AUTOSAR XML (schema 314)
package /ComponentType
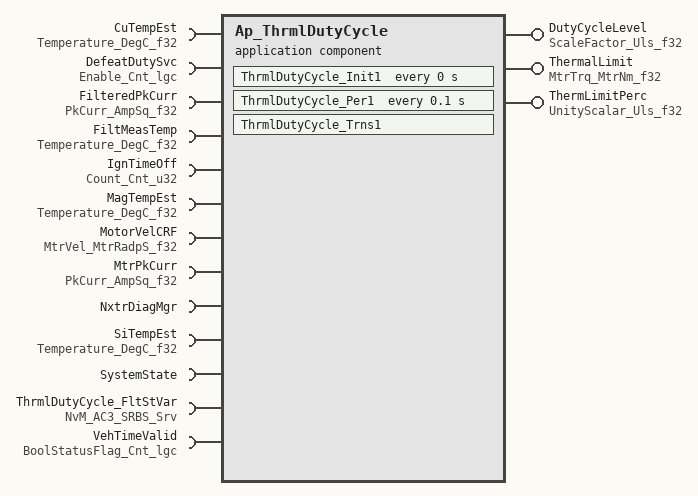
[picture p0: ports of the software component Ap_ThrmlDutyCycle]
  application software component type Ap_ThrmlDutyCycle
    provide port DutyCycleLevel: unqueued-sender-com-spec{data-element=Uls_f32, can-invalidate=false, init-value=D_ZERO_ULS_F32}, provided-interface=ScaleFactor_Uls_f32
    provide port ThermalLimit: unqueued-sender-com-spec{data-element=MtrNm_f32, can-invalidate=false, init-value=D_MTRTRQCMDHILMT_MTRNM_F32}, provided-interface=MtrTrq_MtrNm_f32
    provide port ThermLimitPerc: unqueued-sender-com-spec{data-element=Uls_f32, can-invalidate=false, init-value=D_ZERO_ULS_F32}, provided-interface=UnityScalar_Uls_f32
    13 x require port:
      CuTempEst: unqueued-receiver-com-spec{data-element=DegC_f32, init-value=D_ZERO_ULS_F32}, required-interface=Temperature_DegC_f32
      DefeatDutySvc: unqueued-receiver-com-spec{data-element=Cnt_lgc, init-value=D_FALSE_CNT_LGC}, required-interface=Enable_Cnt_lgc
      FilteredPkCurr: unqueued-receiver-com-spec{data-element=AmpSq_f32, init-value=D_ZERO_ULS_F32}, required-interface=PkCurr_AmpSq_f32
      FiltMeasTemp: unqueued-receiver-com-spec{data-element=DegC_f32, init-value=D_ZERO_ULS_F32}, required-interface=Temperature_DegC_f32
      IgnTimeOff: unqueued-receiver-com-spec{data-element=Cnt_u32, init-value=D_ZERO_CNT_U32}, required-interface=Count_Cnt_u32
      MagTempEst: unqueued-receiver-com-spec{data-element=DegC_f32, init-value=D_ZERO_ULS_F32}, required-interface=Temperature_DegC_f32
      MotorVelCRF: unqueued-receiver-com-spec{data-element=MtrRadpS_f32, init-value=D_ZERO_ULS_F32}, required-interface=MtrVel_MtrRadpS_f32
      MtrPkCurr: unqueued-receiver-com-spec{data-element=AmpSq_f32, init-value=D_ZERO_ULS_F32}, required-interface=PkCurr_AmpSq_f32
      NxtrDiagMgr: required-com-specs=[GetNTCActive, GetNTCFailed, GetNTCStatus, SetNTCStatus], required-interface=NxtrDiagMgr
      SiTempEst: unqueued-receiver-com-spec{data-element=DegC_f32, init-value=D_ZERO_ULS_F32}, required-interface=Temperature_DegC_f32
      SystemState: required-interface=SystemState
      ThrmlDutyCycle_FltStVar: required-com-specs=[EraseBlock, GetErrorStatus, InvalidateNvBlock, ReadBlock, SetRamBlockStatus, WriteBlock], required-interface=NvM_AC3_SRBS_Srv
      VehTimeValid: unqueued-receiver-com-spec{data-element=Cnt_lgc, init-value=D_FALSE_CNT_LGC}, required-interface=BoolStatusFlag_Cnt_lgc
  internal behavior Ap_ThrmlDutyCycle_InternalBehavior: component=Ap_ThrmlDutyCycle
    timing event ThrmlDutyCycle_Init1_InitEvent: start-on-event=ThrmlDutyCycle_Init1, period=0
    timing event TMT_ThrmlDutyCycle_Per1: start-on-event=ThrmlDutyCycle_Per1, period=0.1
    mode switch event MST_ThrmlDutyCycle_Trns1_0: start-on-event=ThrmlDutyCycle_Trns1, activation=ENTRY, mode=SystemState.Mode.OFF
    per instance memory ThrmlDutyCycle_FltStVal: type=ThrmlDutyCycle_FltStVal_Datatype, type-definition=/DataType/ThrmlDutyCycle_FltStVal_Datatype
    port-api-options:
      enable-take-address=false, indirect-api=false, port=CuTempEst
      enable-take-address=false, indirect-api=false, port=DefeatDutySvc
      enable-take-address=false, indirect-api=false, port=DutyCycleLevel
      enable-take-address=false, indirect-api=false, port=FilteredPkCurr
      enable-take-address=false, indirect-api=false, port=FiltMeasTemp
      enable-take-address=false, indirect-api=false, port=IgnTimeOff
      enable-take-address=false, indirect-api=false, port=MagTempEst
      enable-take-address=false, indirect-api=false, port=MotorVelCRF
      enable-take-address=false, indirect-api=false, port=MtrPkCurr
      enable-take-address=false, indirect-api=false, port=NxtrDiagMgr
      enable-take-address=false, indirect-api=false, port=SiTempEst
      enable-take-address=false, indirect-api=false, port=SystemState
      enable-take-address=false, indirect-api=false, port=ThermalLimit
      enable-take-address=false, indirect-api=false, port=ThermLimitPerc
      enable-take-address=false, indirect-api=false, port=ThrmlDutyCycle_FltStVar
      enable-take-address=false, indirect-api=false, port=VehTimeValid
    runnable ThrmlDutyCycle_Init1
      data read access READ_DefeatDutySvc_Cnt_lgc: data-element=DefeatDutySvc.Cnt_lgc
      data read access READ_IgnTimeOff_Cnt_u32: data-element=IgnTimeOff.Cnt_u32
      data read access READ_VehTimeValid_Cnt_lgc: data-element=VehTimeValid.Cnt_lgc
      sync call SC_ThrmlDutyCycle_FltStVar_GetErrorStatus: operation=ThrmlDutyCycle_FltStVar.GetErrorStatus, timeout=0
    runnable ThrmlDutyCycle_Per1
      10 x data read access:
        READ_CuTempEst_DegC_f32: data-element=CuTempEst.DegC_f32
        READ_DefeatDutySvc_Cnt_lgc: data-element=DefeatDutySvc.Cnt_lgc
        READ_FilteredPkCurr_AmpSq_f32: data-element=FilteredPkCurr.AmpSq_f32
        READ_FiltMeasTemp_DegC_f32: data-element=FiltMeasTemp.DegC_f32
        READ_IgnTimeOff_Cnt_u32: data-element=IgnTimeOff.Cnt_u32
        READ_MagTempEst_DegC_f32: data-element=MagTempEst.DegC_f32
        READ_MotorVelCRF_MtrRadpS_f32: data-element=MotorVelCRF.MtrRadpS_f32
        READ_MtrPkCurr_AmpSq_f32: data-element=MtrPkCurr.AmpSq_f32
        READ_SiTempEst_DegC_f32: data-element=SiTempEst.DegC_f32
        READ_VehTimeValid_Cnt_lgc: data-element=VehTimeValid.Cnt_lgc
      data write access WRITE_DutyCycleLevel_Uls_f32: data-element=DutyCycleLevel.Uls_f32
      data write access WRITE_ThermalLimit_MtrNm_f32: data-element=ThermalLimit.MtrNm_f32
      data write access WRITE_ThermLimitPerc_Uls_f32: data-element=ThermLimitPerc.Uls_f32
      sync call SC_NxtrDiagMgr_GetNTCFailed: operation=NxtrDiagMgr.GetNTCFailed, timeout=0
      sync call SC_NxtrDiagMgr_SetNTCStatus: operation=NxtrDiagMgr.SetNTCStatus, timeout=0
    runnable ThrmlDutyCycle_Trns1
      sync call SC_ThrmlDutyCycle_FltStVar_SetRamBlockStatus: operation=ThrmlDutyCycle_FltStVar.SetRamBlockStatus, timeout=0
    service-needss:
      swc nv block needs ThrmlDutyCycle_FltStVar: n-data-sets=0, readonly=false, reliability=LOW, resistant-to-changed-sw=false, restore-at-start=false, write-only-once=false, writing-frequency=0, writing-priority=LOW, mirror-block=ThrmlDutyCycle_FltStVal
  swc implementation Ap_ThrmlDutyCycle_Implementation: behavior=Ap_ThrmlDutyCycle_InternalBehavior
    code-descriptors:
      code Code: type=SRC
